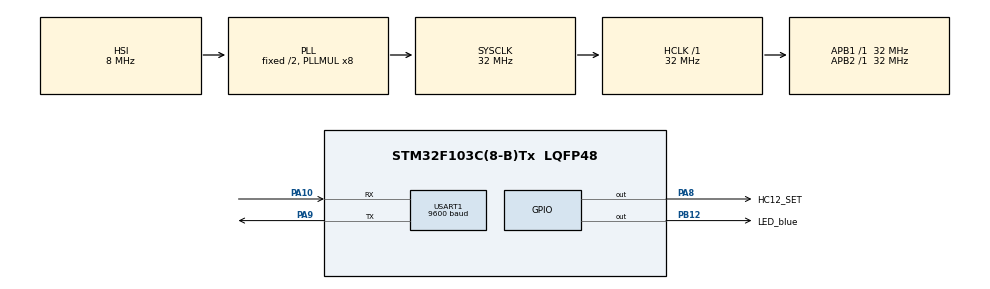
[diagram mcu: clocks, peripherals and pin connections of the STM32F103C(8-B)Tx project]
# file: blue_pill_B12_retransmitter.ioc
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FREERTOS.Tasks01=defaultTask,0,128,StartDefaultTask,Default,NULL,Dynamic,NULL,NULL
Mcu.Family=STM32F1
Mcu.Name=STM32F103C(8-B)Tx
Mcu.Package=LQFP48
NVIC.PriorityGroup=NVIC_PRIORITYGROUP_4
NVIC.TIM4_IRQn=true\:0\:0\:false\:false\:true\:false\:false\:true
NVIC.TimeBase=TIM4_IRQn
NVIC.TimeBaseIP=TIM4
NVIC.USART1_IRQn=true\:5\:0\:false\:false\:true\:true\:true\:true
PA10.Mode=Asynchronous
PA10.Signal=USART1_RX
PA13.Mode=Serial_Wire
PA13.Signal=SYS_JTMS-SWDIO
PA14.Mode=Serial_Wire
PA14.Signal=SYS_JTCK-SWCLK
PA8.GPIO_Label=HC12_SET
PA8.PinState=GPIO_PIN_SET
PA8.Signal=GPIO_Output
PA9.Mode=Asynchronous
PA9.Signal=USART1_TX
PB12.GPIO_Label=LED_blue
PB12.PinState=GPIO_PIN_SET
PB12.Signal=GPIO_Output
ProjectManager.HeapSize=0x200
ProjectManager.StackSize=0x400
ProjectManager.TargetToolchain=MDK-ARM V5.27
RCC.AHBFreq_Value=32000000
RCC.APB1Freq_Value=32000000
RCC.APB1TimFreq_Value=32000000
RCC.APB2Freq_Value=32000000
RCC.APB2TimFreq_Value=32000000
RCC.HCLKFreq_Value=32000000
RCC.PLLMUL=RCC_PLL_MUL8
RCC.SYSCLKFreq_VALUE=32000000
RCC.SYSCLKSource=RCC_SYSCLKSOURCE_PLLCLK
RCC.USBFreq_Value=32000000
USART1.BaudRate=9600
USART1.VirtualMode=VM_ASYNC
VP_FREERTOS_VS_CMSIS_V1.Mode=CMSIS_V1
VP_SYS_VS_tim4.Mode=TIM4
board=custom

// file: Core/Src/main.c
/* USER CODE BEGIN Header */
/**
  ******************************************************************************
  * @file           : main.c
  * @brief          : Main program body
  ******************************************************************************
  * @attention
  *
  * <h2><center>&copy; Copyright (c) 2020 STMicroelectronics.
  * All rights reserved.</center></h2>
  *
  * This software component is licensed by ST under Ultimate Liberty license
  * SLA0044, the "License"; You may not use this file except in compliance with
  * the License. You may obtain a copy of the License at:
  *                             www.st.com/SLA0044
  *
  ******************************************************************************
  */
/* USER CODE END Header */

#include "main.h"
#include "cmsis_os.h"

UART_HandleTypeDef huart1;

osThreadId defaultTaskHandle;

void SystemClock_Config(void);
static void MX_GPIO_Init(void);
static void MX_USART1_UART_Init(void);
void StartDefaultTask(void const * argument);

int main(void)
{

  /* MCU Configuration--------------------------------------------------------*/

  /* Reset of all peripherals, Initializes the Flash interface and the Systick. */
  HAL_Init();

  /* Configure the system clock */
  SystemClock_Config();

  /* Initialize all configured peripherals */
  MX_GPIO_Init();
  MX_USART1_UART_Init();
  /* USER CODE BEGIN 2 */

	USART1->CR1 |= USART_CR1_RXNEIE;

  /* USER CODE END 2 */

  /* Create the thread(s) */
  /* definition and creation of defaultTask */
  osThreadDef(defaultTask, StartDefaultTask, osPriorityNormal, 0, 128);
  defaultTaskHandle = osThreadCreate(osThread(defaultTask), NULL);

  /* Start scheduler */
  osKernelStart();

  /* We should never get here as control is now taken by the scheduler */

  /* Infinite loop */
  while (1)
  {

  }
}

void SystemClock_Config(void)
{
  RCC_OscInitTypeDef RCC_OscInitStruct = {0};
  RCC_ClkInitTypeDef RCC_ClkInitStruct = {0};

  /** Initializes the CPU, AHB and APB busses clocks
  */
  RCC_OscInitStruct.OscillatorType = RCC_OSCILLATORTYPE_HSI;
  RCC_OscInitStruct.HSIState = RCC_HSI_ON;
  RCC_OscInitStruct.HSICalibrationValue = RCC_HSICALIBRATION_DEFAULT;
  RCC_OscInitStruct.PLL.PLLState = RCC_PLL_ON;
  RCC_OscInitStruct.PLL.PLLSource = RCC_PLLSOURCE_HSI_DIV2;
  RCC_OscInitStruct.PLL.PLLMUL = RCC_PLL_MUL8;
  if (HAL_RCC_OscConfig(&RCC_OscInitStruct) != HAL_OK)
  {
    Error_Handler();
  }
  /** Initializes the CPU, AHB and APB busses clocks
  */
  RCC_ClkInitStruct.ClockType = RCC_CLOCKTYPE_HCLK|RCC_CLOCKTYPE_SYSCLK
                              |RCC_CLOCKTYPE_PCLK1|RCC_CLOCKTYPE_PCLK2;
  RCC_ClkInitStruct.SYSCLKSource = RCC_SYSCLKSOURCE_PLLCLK;
  RCC_ClkInitStruct.AHBCLKDivider = RCC_SYSCLK_DIV1;
  RCC_ClkInitStruct.APB1CLKDivider = RCC_HCLK_DIV1;
  RCC_ClkInitStruct.APB2CLKDivider = RCC_HCLK_DIV1;

  if (HAL_RCC_ClockConfig(&RCC_ClkInitStruct, FLASH_LATENCY_1) != HAL_OK)
  {
    Error_Handler();
  }
}

static void MX_USART1_UART_Init(void)
{

  huart1.Instance = USART1;
  huart1.Init.BaudRate = 9600;
  huart1.Init.WordLength = UART_WORDLENGTH_8B;
  huart1.Init.StopBits = UART_STOPBITS_1;
  huart1.Init.Parity = UART_PARITY_NONE;
  huart1.Init.Mode = UART_MODE_TX_RX;
  huart1.Init.HwFlowCtl = UART_HWCONTROL_NONE;
  huart1.Init.OverSampling = UART_OVERSAMPLING_16;
  if (HAL_UART_Init(&huart1) != HAL_OK)
  {
    Error_Handler();
  }

}

static void MX_GPIO_Init(void)
{
  GPIO_InitTypeDef GPIO_InitStruct = {0};

  /* GPIO Ports Clock Enable */
  __HAL_RCC_GPIOB_CLK_ENABLE();
  __HAL_RCC_GPIOA_CLK_ENABLE();

  /*Configure GPIO pin Output Level */
  HAL_GPIO_WritePin(LED_blue_GPIO_Port, LED_blue_Pin, GPIO_PIN_SET);

  /*Configure GPIO pin Output Level */
  HAL_GPIO_WritePin(HC12_SET_GPIO_Port, HC12_SET_Pin, GPIO_PIN_SET);

  /*Configure GPIO pin : LED_blue_Pin */
  GPIO_InitStruct.Pin = LED_blue_Pin;
  GPIO_InitStruct.Mode = GPIO_MODE_OUTPUT_PP;
  GPIO_InitStruct.Pull = GPIO_NOPULL;
  GPIO_InitStruct.Speed = GPIO_SPEED_FREQ_LOW;
  HAL_GPIO_Init(LED_blue_GPIO_Port, &GPIO_InitStruct);

  /*Configure GPIO pin : HC12_SET_Pin */
  GPIO_InitStruct.Pin = HC12_SET_Pin;
  GPIO_InitStruct.Mode = GPIO_MODE_OUTPUT_PP;
  GPIO_InitStruct.Pull = GPIO_NOPULL;
  GPIO_InitStruct.Speed = GPIO_SPEED_FREQ_LOW;
  HAL_GPIO_Init(HC12_SET_GPIO_Port, &GPIO_InitStruct);

}

void StartDefaultTask(void const * argument)
{
  /* USER CODE BEGIN 5 */
  /* Infinite loop */
  for(;;)
  {
		//HAL_GPIO_TogglePin(LED_blue_GPIO_Port, LED_blue_Pin);

    osDelay(1000);
  }
  /* USER CODE END 5 */
}

void HAL_TIM_PeriodElapsedCallback(TIM_HandleTypeDef *htim)
{
  if (htim->Instance == TIM4) {
    HAL_IncTick();
  }
}

void Error_Handler(void)
{
}

/************************ (C) COPYRIGHT STMicroelectronics *****END OF FILE****/
